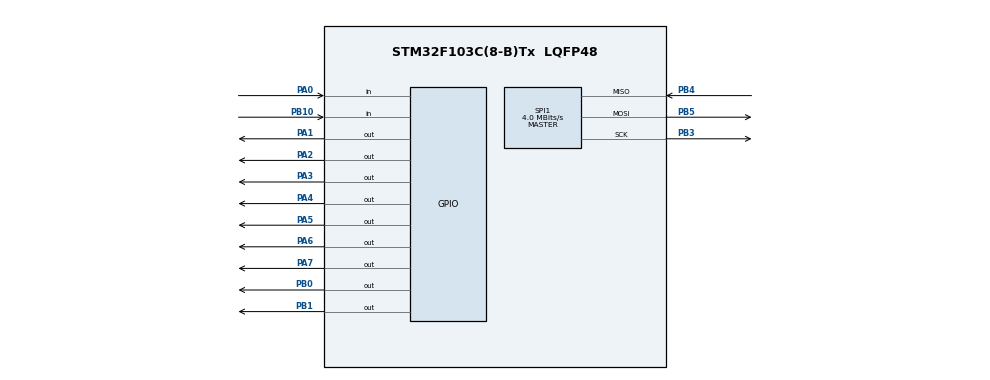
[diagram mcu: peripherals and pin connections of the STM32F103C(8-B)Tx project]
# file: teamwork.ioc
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Dma.Request0=SPI1_RX
Dma.Request1=SPI1_TX
Dma.SPI1_RX.0.Direction=DMA_PERIPH_TO_MEMORY
Dma.SPI1_RX.0.Instance=DMA1_Channel2
Dma.SPI1_RX.0.MemDataAlignment=DMA_MDATAALIGN_BYTE
Dma.SPI1_RX.0.MemInc=DMA_MINC_ENABLE
Dma.SPI1_RX.0.Mode=DMA_NORMAL
Dma.SPI1_RX.0.PeriphDataAlignment=DMA_PDATAALIGN_BYTE
Dma.SPI1_RX.0.PeriphInc=DMA_PINC_DISABLE
Dma.SPI1_RX.0.Priority=DMA_PRIORITY_LOW
Dma.SPI1_TX.1.Direction=DMA_MEMORY_TO_PERIPH
Dma.SPI1_TX.1.Instance=DMA1_Channel3
Dma.SPI1_TX.1.MemDataAlignment=DMA_MDATAALIGN_BYTE
Dma.SPI1_TX.1.MemInc=DMA_MINC_ENABLE
Dma.SPI1_TX.1.Mode=DMA_NORMAL
Dma.SPI1_TX.1.PeriphDataAlignment=DMA_PDATAALIGN_BYTE
Dma.SPI1_TX.1.PeriphInc=DMA_PINC_DISABLE
Dma.SPI1_TX.1.Priority=DMA_PRIORITY_LOW
Mcu.Family=STM32F1
Mcu.Name=STM32F103C(8-B)Tx
Mcu.Package=LQFP48
NVIC.DMA1_Channel2_IRQn=true\:0\:0\:false\:false\:true\:false\:true\:true
NVIC.DMA1_Channel3_IRQn=true\:0\:0\:false\:false\:true\:false\:true\:true
NVIC.PriorityGroup=NVIC_PRIORITYGROUP_4
PA0-WKUP.GPIO_PuPd=GPIO_PULLDOWN
PA0-WKUP.Signal=GPIO_Input
PA1.Signal=GPIO_Output
PA13.Mode=Serial_Wire
PA13.Signal=SYS_JTMS-SWDIO
PA14.Mode=Serial_Wire
PA14.Signal=SYS_JTCK-SWCLK
PA2.PinState=GPIO_PIN_SET
PA2.Signal=GPIO_Output
PA3.Signal=GPIO_Output
PA4.Signal=GPIO_Output
PA5.Signal=GPIO_Output
PA6.Signal=GPIO_Output
PA7.GPIO_Speed=GPIO_SPEED_FREQ_LOW
PA7.PinState=GPIO_PIN_SET
PA7.Signal=GPIO_Output
PB0.Signal=GPIO_Output
PB1.Signal=GPIO_Output
PB10.Signal=GPIO_Input
PB3.Mode=Full_Duplex_Master
PB3.Signal=SPI1_SCK
PB4.Mode=Full_Duplex_Master
PB4.Signal=SPI1_MISO
PB5.Mode=Full_Duplex_Master
PB5.Signal=SPI1_MOSI
PD0-OSC_IN.Mode=HSE-External-Oscillator
PD0-OSC_IN.Signal=RCC_OSC_IN
PD1-OSC_OUT.Mode=HSE-External-Oscillator
PD1-OSC_OUT.Signal=RCC_OSC_OUT
ProjectManager.HeapSize=0x200
ProjectManager.StackSize=0x400
ProjectManager.TargetToolchain=CMake
RCC.APB1Freq_Value=8000000
RCC.APB1TimFreq_Value=8000000
RCC.APB2Freq_Value=8000000
SPI1.CalculateBaudRate=4.0 MBits/s
SPI1.Direction=SPI_DIRECTION_2LINES
SPI1.Mode=SPI_MODE_MASTER
SPI1.VirtualType=VM_MASTER
TIM2.ClockDivision=TIM_CLOCKDIVISION_DIV1
TIM2.Prescaler=7
VP_TIM2_VS_ClockSourceINT.Mode=Internal
board=custom

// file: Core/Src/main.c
/* USER CODE BEGIN Header */
/**
  ******************************************************************************
  * @file           : main.c
  * @brief          : Main program body
  ******************************************************************************
  * @attention
  *
  * Copyright (c) 2026 STMicroelectronics.
  * All rights reserved.
  *
  * This software is licensed under terms that can be found in the LICENSE file
  * in the root directory of this software component.
  * If no LICENSE file comes with this software, it is provided AS-IS.
  *
  ******************************************************************************
  */
/* USER CODE END Header */
#include "main.h"

/* USER CODE BEGIN Includes */

#include "bsp.h"
#include "../../Core/Inc/stm32f1xx_it.h"

/* USER CODE END Includes */

SPI_HandleTypeDef hspi1;
DMA_HandleTypeDef hdma_spi1_rx;
DMA_HandleTypeDef hdma_spi1_tx;

TIM_HandleTypeDef htim2;

void SystemClock_Config(void);
static void MX_GPIO_Init(void);
static void MX_DMA_Init(void);
static void MX_TIM2_Init(void);
static void MX_SPI1_Init(void);

int main(void)
{

  /* MCU Configuration--------------------------------------------------------*/

  /* Reset of all peripherals, Initializes the Flash interface and the Systick. */
  HAL_Init();

  /* Configure the system clock */
  SystemClock_Config();

  /* Initialize all configured peripherals */
  MX_GPIO_Init();
  MX_DMA_Init();
  MX_TIM2_Init();
  MX_SPI1_Init();
  /* USER CODE BEGIN 2 */

  /* led初始化 / LED initialization */
  /* Initialize the LEDs. */
  LED_Init(&white_led,GPIOB,GPIO_PIN_0, 0);
  LED_Init(&user_led[0],GPIOA,GPIO_PIN_1, 0);
  LED_Init(&user_led[1],GPIOA,GPIO_PIN_2, 0);
  LED_Init(&user_led[2],GPIOA,GPIO_PIN_3, 0);
  LED_Init(&user_led[3],GPIOA,GPIO_PIN_4, 0);
  LED_Init(&user_led[4],GPIOA,GPIO_PIN_5, 0);
  LED_Init(&user_led[5],GPIOA,GPIO_PIN_6, 0);
  Key_Init(&key_1 ,GPIOA ,GPIO_PIN_0);
  HC_SR04_INIT(&user_hc_sr04,&htim2,GPIOB,GPIO_PIN_1,GPIOB,GPIO_PIN_10);

  /* USER CODE END 2 */

  /* Infinite loop */
  /* USER CODE BEGIN WHILE */
  while (1)
  {
    /* 无限循环 / Infinite loop */
    HC_SR04_getlength(&user_hc_sr04);
    /* USER CODE END WHILE */

  }
}

void SystemClock_Config(void)
{
  RCC_OscInitTypeDef RCC_OscInitStruct = {0};
  RCC_ClkInitTypeDef RCC_ClkInitStruct = {0};

  /** Initializes the RCC Oscillators according to the specified parameters
  * in the RCC_OscInitTypeDef structure.
  */
  RCC_OscInitStruct.OscillatorType = RCC_OSCILLATORTYPE_HSI;
  RCC_OscInitStruct.HSIState = RCC_HSI_ON;
  RCC_OscInitStruct.HSICalibrationValue = RCC_HSICALIBRATION_DEFAULT;
  RCC_OscInitStruct.PLL.PLLState = RCC_PLL_NONE;
  if (HAL_RCC_OscConfig(&RCC_OscInitStruct) != HAL_OK)
  {
    Error_Handler();
  }

  /** Initializes the CPU, AHB and APB buses clocks
  */
  RCC_ClkInitStruct.ClockType = RCC_CLOCKTYPE_HCLK|RCC_CLOCKTYPE_SYSCLK
                              |RCC_CLOCKTYPE_PCLK1|RCC_CLOCKTYPE_PCLK2;
  RCC_ClkInitStruct.SYSCLKSource = RCC_SYSCLKSOURCE_HSI;
  RCC_ClkInitStruct.AHBCLKDivider = RCC_SYSCLK_DIV1;
  RCC_ClkInitStruct.APB1CLKDivider = RCC_HCLK_DIV1;
  RCC_ClkInitStruct.APB2CLKDivider = RCC_HCLK_DIV1;

  if (HAL_RCC_ClockConfig(&RCC_ClkInitStruct, FLASH_LATENCY_0) != HAL_OK)
  {
    Error_Handler();
  }
}

static void MX_SPI1_Init(void)
{

  /* SPI1 parameter configuration*/
  hspi1.Instance = SPI1;
  hspi1.Init.Mode = SPI_MODE_MASTER;
  hspi1.Init.Direction = SPI_DIRECTION_2LINES;
  hspi1.Init.DataSize = SPI_DATASIZE_8BIT;
  hspi1.Init.CLKPolarity = SPI_POLARITY_LOW;
  hspi1.Init.CLKPhase = SPI_PHASE_1EDGE;
  hspi1.Init.NSS = SPI_NSS_SOFT;
  hspi1.Init.BaudRatePrescaler = SPI_BAUDRATEPRESCALER_2;
  hspi1.Init.FirstBit = SPI_FIRSTBIT_MSB;
  hspi1.Init.TIMode = SPI_TIMODE_DISABLE;
  hspi1.Init.CRCCalculation = SPI_CRCCALCULATION_DISABLE;
  hspi1.Init.CRCPolynomial = 10;
  if (HAL_SPI_Init(&hspi1) != HAL_OK)
  {
    Error_Handler();
  }

}

static void MX_TIM2_Init(void)
{

  TIM_ClockConfigTypeDef sClockSourceConfig = {0};
  TIM_MasterConfigTypeDef sMasterConfig = {0};

  htim2.Instance = TIM2;
  htim2.Init.Prescaler = 7;
  htim2.Init.CounterMode = TIM_COUNTERMODE_UP;
  htim2.Init.Period = 65535;
  htim2.Init.ClockDivision = TIM_CLOCKDIVISION_DIV1;
  htim2.Init.AutoReloadPreload = TIM_AUTORELOAD_PRELOAD_DISABLE;
  if (HAL_TIM_Base_Init(&htim2) != HAL_OK)
  {
    Error_Handler();
  }
  sClockSourceConfig.ClockSource = TIM_CLOCKSOURCE_INTERNAL;
  if (HAL_TIM_ConfigClockSource(&htim2, &sClockSourceConfig) != HAL_OK)
  {
    Error_Handler();
  }
  sMasterConfig.MasterOutputTrigger = TIM_TRGO_RESET;
  sMasterConfig.MasterSlaveMode = TIM_MASTERSLAVEMODE_DISABLE;
  if (HAL_TIMEx_MasterConfigSynchronization(&htim2, &sMasterConfig) != HAL_OK)
  {
    Error_Handler();
  }

}

static void MX_DMA_Init(void)
{

  /* DMA controller clock enable */
  __HAL_RCC_DMA1_CLK_ENABLE();

  /* DMA interrupt init */
  /* DMA1_Channel2_IRQn interrupt configuration */
  HAL_NVIC_SetPriority(DMA1_Channel2_IRQn, 0, 0);
  HAL_NVIC_EnableIRQ(DMA1_Channel2_IRQn);
  /* DMA1_Channel3_IRQn interrupt configuration */
  HAL_NVIC_SetPriority(DMA1_Channel3_IRQn, 0, 0);
  HAL_NVIC_EnableIRQ(DMA1_Channel3_IRQn);

}

static void MX_GPIO_Init(void)
{
  GPIO_InitTypeDef GPIO_InitStruct = {0};

  /* GPIO Ports Clock Enable */
  __HAL_RCC_GPIOD_CLK_ENABLE();
  __HAL_RCC_GPIOA_CLK_ENABLE();
  __HAL_RCC_GPIOB_CLK_ENABLE();

  /*Configure GPIO pin Output Level */
  HAL_GPIO_WritePin(GPIOA, GPIO_PIN_1|GPIO_PIN_3|GPIO_PIN_4|GPIO_PIN_5
                          |GPIO_PIN_6, GPIO_PIN_RESET);

  /*Configure GPIO pin Output Level */
  HAL_GPIO_WritePin(GPIOA, GPIO_PIN_2|GPIO_PIN_7, GPIO_PIN_SET);

  /*Configure GPIO pin Output Level */
  HAL_GPIO_WritePin(GPIOB, GPIO_PIN_0|GPIO_PIN_1, GPIO_PIN_RESET);

  /*Configure GPIO pin : PA0 */
  GPIO_InitStruct.Pin = GPIO_PIN_0;
  GPIO_InitStruct.Mode = GPIO_MODE_INPUT;
  GPIO_InitStruct.Pull = GPIO_PULLDOWN;
  HAL_GPIO_Init(GPIOA, &GPIO_InitStruct);

  /*Configure GPIO pins : PA1 PA2 PA3 PA4
                           PA5 PA6 PA7 */
  GPIO_InitStruct.Pin = GPIO_PIN_1|GPIO_PIN_2|GPIO_PIN_3|GPIO_PIN_4
                          |GPIO_PIN_5|GPIO_PIN_6|GPIO_PIN_7;
  GPIO_InitStruct.Mode = GPIO_MODE_OUTPUT_PP;
  GPIO_InitStruct.Pull = GPIO_NOPULL;
  GPIO_InitStruct.Speed = GPIO_SPEED_FREQ_LOW;
  HAL_GPIO_Init(GPIOA, &GPIO_InitStruct);

  /*Configure GPIO pins : PB0 PB1 */
  GPIO_InitStruct.Pin = GPIO_PIN_0|GPIO_PIN_1;
  GPIO_InitStruct.Mode = GPIO_MODE_OUTPUT_PP;
  GPIO_InitStruct.Pull = GPIO_NOPULL;
  GPIO_InitStruct.Speed = GPIO_SPEED_FREQ_LOW;
  HAL_GPIO_Init(GPIOB, &GPIO_InitStruct);

  /*Configure GPIO pin : PB10 */
  GPIO_InitStruct.Pin = GPIO_PIN_10;
  GPIO_InitStruct.Mode = GPIO_MODE_INPUT;
  GPIO_InitStruct.Pull = GPIO_NOPULL;
  HAL_GPIO_Init(GPIOB, &GPIO_InitStruct);

}

void Error_Handler(void)
{
  __disable_irq();
  while (1)
  {
  }
}
